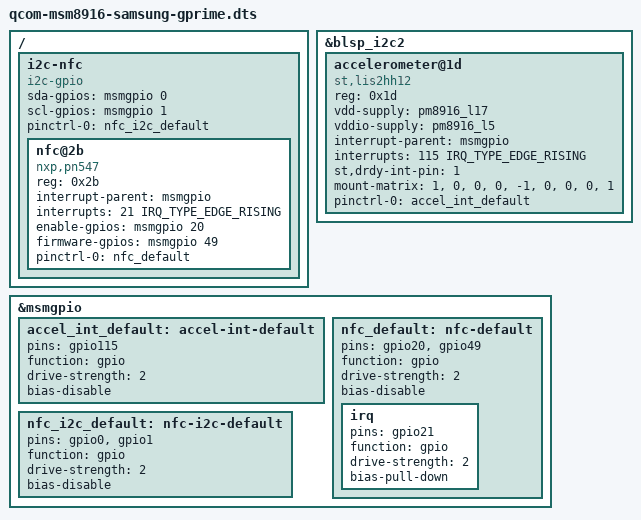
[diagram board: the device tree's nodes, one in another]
// SPDX-License-Identifier: GPL-2.0-only
#include "arm64/qcom/msm8916-samsung-gprime.dts"
#include "qcom-msm8916-smp.dtsi"

/ {
	i2c-nfc {
		compatible = "i2c-gpio";
		sda-gpios = <&msmgpio 0 (GPIO_ACTIVE_HIGH|GPIO_OPEN_DRAIN)>;
		scl-gpios = <&msmgpio 1 (GPIO_ACTIVE_HIGH|GPIO_OPEN_DRAIN)>;

		pinctrl-names = "default";
		pinctrl-0 = <&nfc_i2c_default>;

		#address-cells = <1>;
		#size-cells = <0>;

		nfc@2b {
			compatible = "nxp,pn547", "nxp,nxp-nci-i2c";
			reg = <0x2b>;

			interrupt-parent = <&msmgpio>;
			interrupts = <21 IRQ_TYPE_EDGE_RISING>;

			enable-gpios = <&msmgpio 20 GPIO_ACTIVE_HIGH>;
			firmware-gpios = <&msmgpio 49 GPIO_ACTIVE_HIGH>;

			pinctrl-names = "default";
			pinctrl-0 = <&nfc_default>;
		};
	};
};

&blsp_i2c2 {
	status = "okay";

	accelerometer@1d {
		compatible = "st,lis2hh12";
		reg = <0x1d>;

		vdd-supply = <&pm8916_l17>;
		vddio-supply = <&pm8916_l5>;

		interrupt-parent = <&msmgpio>;
		interrupts = <115 IRQ_TYPE_EDGE_RISING>;
		interrupt-names = "INT1";

		st,drdy-int-pin = <1>;
		mount-matrix = "1", "0", "0",
			      "0", "-1", "0",
			       "0", "0", "1";

		pinctrl-names = "default";
		pinctrl-0 = <&accel_int_default>;
	};
};

&msmgpio {
	accel_int_default: accel-int-default {
		pins = "gpio115";
		function = "gpio";

		drive-strength = <2>;
		bias-disable;
	};

	nfc_default: nfc-default {
		pins = "gpio20", "gpio49";
		function = "gpio";

		drive-strength = <2>;
		bias-disable;

		irq {
			pins = "gpio21";
			function = "gpio";

			drive-strength = <2>;
			bias-pull-down;
		};
	};

	nfc_i2c_default: nfc-i2c-default {
		pins = "gpio0", "gpio1";
		function = "gpio";

		drive-strength = <2>;
		bias-disable;
	};
};
